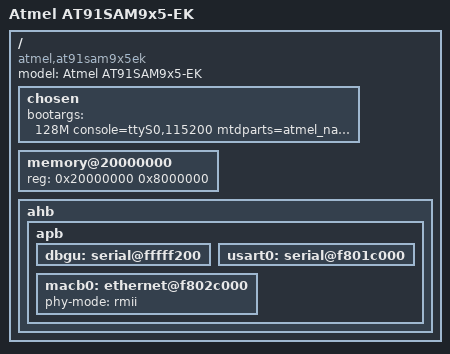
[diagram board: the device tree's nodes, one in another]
/*
 * at91sam9x5ek.dts - Device Tree file for AT91SAM9x5-EK board
 *
 *  Copyright (C) 2012 Atmel,
 *                2012 Nicolas Ferre <nicolas.ferre@atmel.com>
 *
 * Licensed under GPLv2 or later.
 */
/dts-v1/;
/include/ "at91sam9x5.dtsi"

/ {
	model = "Atmel AT91SAM9x5-EK";
	compatible = "atmel,at91sam9x5ek", "atmel,at91sam9x5", "atmel,at91sam9";

	chosen {
		bootargs = "128M console=ttyS0,115200 mtdparts=atmel_nand:8M(bootstrap/uboot/kernel)ro,-(rootfs) root=/dev/mtdblock1 rw rootfstype=ubifs ubi.mtd=1 root=ubi0:rootfs";
	};

	memory@20000000 {
		reg = <0x20000000 0x8000000>;
	};

	ahb {
		apb {
			dbgu: serial@fffff200 {
				status = "okay";
			};

			usart0: serial@f801c000 {
				status = "okay";
			};

			macb0: ethernet@f802c000 {
				phy-mode = "rmii";
				status = "okay";
			};
		};
	};
};
